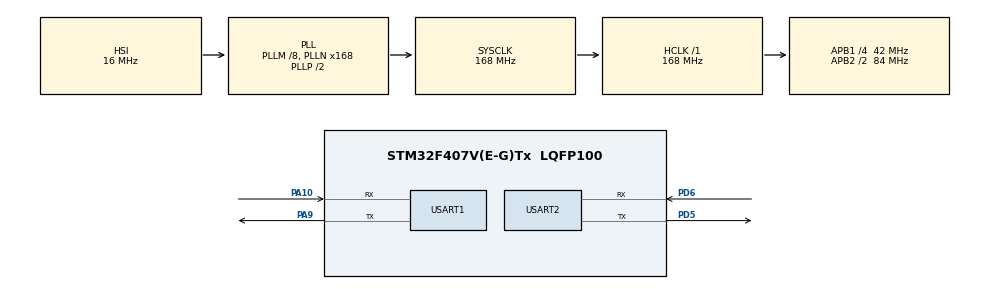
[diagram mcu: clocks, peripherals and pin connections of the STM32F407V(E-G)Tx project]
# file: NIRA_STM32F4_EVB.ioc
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Dma.Request0=USART2_RX
Dma.Request1=USART2_TX
Dma.Request2=USART1_RX
Dma.Request3=USART1_TX
Dma.USART1_RX.2.Direction=DMA_PERIPH_TO_MEMORY
Dma.USART1_RX.2.FIFOMode=DMA_FIFOMODE_DISABLE
Dma.USART1_RX.2.Instance=DMA2_Stream2
Dma.USART1_RX.2.MemDataAlignment=DMA_MDATAALIGN_BYTE
Dma.USART1_RX.2.MemInc=DMA_MINC_ENABLE
Dma.USART1_RX.2.Mode=DMA_NORMAL
Dma.USART1_RX.2.PeriphDataAlignment=DMA_PDATAALIGN_BYTE
Dma.USART1_RX.2.PeriphInc=DMA_PINC_DISABLE
Dma.USART1_RX.2.Priority=DMA_PRIORITY_LOW
Dma.USART1_TX.3.Direction=DMA_MEMORY_TO_PERIPH
Dma.USART1_TX.3.FIFOMode=DMA_FIFOMODE_DISABLE
Dma.USART1_TX.3.Instance=DMA2_Stream7
Dma.USART1_TX.3.MemDataAlignment=DMA_MDATAALIGN_BYTE
Dma.USART1_TX.3.MemInc=DMA_MINC_ENABLE
Dma.USART1_TX.3.Mode=DMA_NORMAL
Dma.USART1_TX.3.PeriphDataAlignment=DMA_PDATAALIGN_BYTE
Dma.USART1_TX.3.PeriphInc=DMA_PINC_DISABLE
Dma.USART1_TX.3.Priority=DMA_PRIORITY_LOW
Dma.USART2_RX.0.Direction=DMA_PERIPH_TO_MEMORY
Dma.USART2_RX.0.FIFOMode=DMA_FIFOMODE_DISABLE
Dma.USART2_RX.0.Instance=DMA1_Stream5
Dma.USART2_RX.0.MemDataAlignment=DMA_MDATAALIGN_BYTE
Dma.USART2_RX.0.MemInc=DMA_MINC_ENABLE
Dma.USART2_RX.0.Mode=DMA_NORMAL
Dma.USART2_RX.0.PeriphDataAlignment=DMA_PDATAALIGN_BYTE
Dma.USART2_RX.0.PeriphInc=DMA_PINC_DISABLE
Dma.USART2_RX.0.Priority=DMA_PRIORITY_LOW
Dma.USART2_TX.1.Direction=DMA_MEMORY_TO_PERIPH
Dma.USART2_TX.1.FIFOMode=DMA_FIFOMODE_DISABLE
Dma.USART2_TX.1.Instance=DMA1_Stream6
Dma.USART2_TX.1.MemDataAlignment=DMA_MDATAALIGN_BYTE
Dma.USART2_TX.1.MemInc=DMA_MINC_ENABLE
Dma.USART2_TX.1.Mode=DMA_NORMAL
Dma.USART2_TX.1.PeriphDataAlignment=DMA_PDATAALIGN_BYTE
Dma.USART2_TX.1.PeriphInc=DMA_PINC_DISABLE
Dma.USART2_TX.1.Priority=DMA_PRIORITY_LOW
Mcu.Family=STM32F4
Mcu.Name=STM32F407V(E-G)Tx
Mcu.Package=LQFP100
NVIC.DMA1_Stream5_IRQn=true\:0\:0\:false\:false\:true\:false\:true\:true
NVIC.DMA1_Stream6_IRQn=true\:0\:0\:false\:false\:true\:false\:true\:true
NVIC.DMA2_Stream2_IRQn=true\:0\:0\:false\:false\:true\:false\:true\:true
NVIC.DMA2_Stream7_IRQn=true\:0\:0\:false\:false\:true\:false\:true\:true
NVIC.PriorityGroup=NVIC_PRIORITYGROUP_4
NVIC.USART1_IRQn=true\:0\:0\:false\:false\:true\:true\:true\:true
NVIC.USART2_IRQn=true\:0\:0\:false\:false\:true\:true\:true\:true
PA10.Mode=Asynchronous
PA10.Signal=USART1_RX
PA13.Mode=Serial_Wire
PA13.Signal=SYS_JTMS-SWDIO
PA14.Mode=Serial_Wire
PA14.Signal=SYS_JTCK-SWCLK
PA9.Mode=Asynchronous
PA9.Signal=USART1_TX
PD5.Mode=Asynchronous
PD5.Signal=USART2_TX
PD6.Mode=Asynchronous
PD6.Signal=USART2_RX
PH0-OSC_IN.Mode=HSE-External-Oscillator
PH0-OSC_IN.Signal=RCC_OSC_IN
PH1-OSC_OUT.Mode=HSE-External-Oscillator
PH1-OSC_OUT.Signal=RCC_OSC_OUT
ProjectManager.HeapSize=0x200
ProjectManager.StackSize=0x400
ProjectManager.TargetToolchain=MDK-ARM V5.32
RCC.48MHZClocksFreq_Value=84000000
RCC.AHBFreq_Value=168000000
RCC.APB1CLKDivider=RCC_HCLK_DIV4
RCC.APB1Freq_Value=42000000
RCC.APB1TimFreq_Value=84000000
RCC.APB2CLKDivider=RCC_HCLK_DIV2
RCC.APB2Freq_Value=84000000
RCC.APB2TimFreq_Value=168000000
RCC.CortexFreq_Value=168000000
RCC.HCLKFreq_Value=168000000
RCC.HSE_VALUE=25000000
RCC.HSI_VALUE=16000000
RCC.LSE_VALUE=32768
RCC.PLLM=8
RCC.PLLN=168
RCC.SYSCLKFreq_VALUE=168000000
RCC.SYSCLKSource=RCC_SYSCLKSOURCE_PLLCLK
RCC.VCOOutputFreq_Value=336000000
USART1.VirtualMode=VM_ASYNC
USART2.VirtualMode=VM_ASYNC
board=custom

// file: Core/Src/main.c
/* USER CODE BEGIN Header */
/**
  ******************************************************************************
  * @file           : main.c
  * @brief          : Main program body
  ******************************************************************************
  * @attention
  *
  * Copyright (c) 2023 STMicroelectronics.
  * All rights reserved.
  *
  * This software is licensed under terms that can be found in the LICENSE file
  * in the root directory of this software component.
  * If no LICENSE file comes with this software, it is provided AS-IS.
  *
  ******************************************************************************
  */
/* USER CODE END Header */
#include "main.h"
#include "dma.h"
#include "usart.h"
#include "gpio.h"

/* USER CODE BEGIN Includes */
#include "ril.h"
/* USER CODE END Includes */

void SystemClock_Config(void);

int main(void)
{

  /* MCU Configuration--------------------------------------------------------*/

  /* Reset of all peripherals, Initializes the Flash interface and the Systick. */
  HAL_Init();

  /* Configure the system clock */
  SystemClock_Config();

  /* Initialize all configured peripherals */
  MX_GPIO_Init();
  MX_DMA_Init();
  MX_USART2_UART_Init();
  MX_USART1_UART_Init();
  /* USER CODE BEGIN 2 */
  RIL_initialize(&huart1);
  /* USER CODE END 2 */

  /* Infinite loop */
  while (1)
  {

  }
}

void SystemClock_Config(void)
{
  RCC_OscInitTypeDef RCC_OscInitStruct = {0};
  RCC_ClkInitTypeDef RCC_ClkInitStruct = {0};

  /** Configure the main internal regulator output voltage
  */
  __HAL_RCC_PWR_CLK_ENABLE();
  __HAL_PWR_VOLTAGESCALING_CONFIG(PWR_REGULATOR_VOLTAGE_SCALE1);

  /** Initializes the RCC Oscillators according to the specified parameters
  * in the RCC_OscInitTypeDef structure.
  */
  RCC_OscInitStruct.OscillatorType = RCC_OSCILLATORTYPE_HSI;
  RCC_OscInitStruct.HSIState = RCC_HSI_ON;
  RCC_OscInitStruct.HSICalibrationValue = RCC_HSICALIBRATION_DEFAULT;
  RCC_OscInitStruct.PLL.PLLState = RCC_PLL_ON;
  RCC_OscInitStruct.PLL.PLLSource = RCC_PLLSOURCE_HSI;
  RCC_OscInitStruct.PLL.PLLM = 8;
  RCC_OscInitStruct.PLL.PLLN = 168;
  RCC_OscInitStruct.PLL.PLLP = RCC_PLLP_DIV2;
  RCC_OscInitStruct.PLL.PLLQ = 4;
  if (HAL_RCC_OscConfig(&RCC_OscInitStruct) != HAL_OK)
  {
    Error_Handler();
  }

  /** Initializes the CPU, AHB and APB buses clocks
  */
  RCC_ClkInitStruct.ClockType = RCC_CLOCKTYPE_HCLK|RCC_CLOCKTYPE_SYSCLK
                              |RCC_CLOCKTYPE_PCLK1|RCC_CLOCKTYPE_PCLK2;
  RCC_ClkInitStruct.SYSCLKSource = RCC_SYSCLKSOURCE_PLLCLK;
  RCC_ClkInitStruct.AHBCLKDivider = RCC_SYSCLK_DIV1;
  RCC_ClkInitStruct.APB1CLKDivider = RCC_HCLK_DIV4;
  RCC_ClkInitStruct.APB2CLKDivider = RCC_HCLK_DIV2;

  if (HAL_RCC_ClockConfig(&RCC_ClkInitStruct, FLASH_LATENCY_5) != HAL_OK)
  {
    Error_Handler();
  }
}

/* USER CODE BEGIN 4 */
void HAL_UART_RxCpltCallback(UART_HandleTypeDef* huart){
  switch((uint32_t)huart->Instance){
    case USART1_BASE:
      RIL_rxCpltHandle();
      break;
  }
}

void HAL_UART_TxCpltCallback(UART_HandleTypeDef* huart)
  {
  switch((uint32_t)huart->Instance){
    case USART1_BASE:
       RIL_txCpltHandle();
      break;
  }
}
/* USER CODE END 4 */

void Error_Handler(void)
{
  __disable_irq();
  while (1)
  {
  }
}
